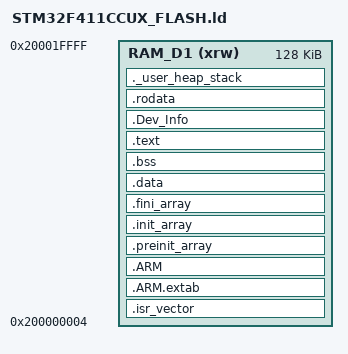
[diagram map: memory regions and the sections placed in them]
/*
******************************************************************************
**
** @file        : LinkerScript.ld
**
** @author      : Auto-generated by STM32CubeIDE
**
** @brief       : Linker script for STM32F411CCUx Device from STM32F4 series
**                      256Kbytes FLASH
**                      128Kbytes RAM
**
**                Set heap size, stack size and stack location according
**                to application requirements.
**
**                Set memory bank area and size if external memory is used
**
**  Target      : STMicroelectronics STM32
**
**  Distribution: The file is distributed as is, without any warranty
**                of any kind.
**
******************************************************************************
** @attention
**
** Copyright (c) 2023 STMicroelectronics.
** All rights reserved.
**
** This software is licensed under terms that can be found in the LICENSE file
** in the root directory of this software component.
** If no LICENSE file comes with this software, it is provided AS-IS.
**
******************************************************************************
*/

/* Entry Point */
ENTRY(Init)

/* Generate 2 segment for loader code and device info */
PHDRS {Loader PT_LOAD ; SgInfo PT_LOAD ; }

/* Highest address of the user mode stack */
_estack = ORIGIN(RAM_D1) + LENGTH(RAM_D1); /* end of "RAM" Ram type memory */

_Min_Heap_Size = 0x200; /* required amount of heap */
_Min_Stack_Size = 0x400; /* required amount of stack */

/* Memories definition */
MEMORY
{
  RAM_D1    (xrw)    : ORIGIN = 0x200000004,   LENGTH = 128K-4
}

/* Sections */
SECTIONS
{
  /* The startup code into "FLASH" Rom type memory */
  .isr_vector :
  {
  	. = . + 0x1FC; /* ISR vector offset */
    . = ALIGN(4);
    KEEP(*(.isr_vector)) /* Startup code */
    . = ALIGN(4);
  } >RAM_D1 :Loader

  .ARM.extab   : {
    . = ALIGN(4);
    *(.ARM.extab* .gnu.linkonce.armextab.*)
    . = ALIGN(4);
  } >RAM_D1 :Loader

  .ARM : {
    __exidx_start = .;
    *(.ARM.exidx*)
    __exidx_end = .;
  } >RAM_D1 :Loader

  .preinit_array     :
  {
    PROVIDE_HIDDEN (__preinit_array_start = .);
    KEEP (*(.preinit_array*))
    PROVIDE_HIDDEN (__preinit_array_end = .);
  } >RAM_D1 :Loader

  .init_array :
  {
    PROVIDE_HIDDEN (__init_array_start = .);
    KEEP (*(SORT(.init_array.*)))
    KEEP (*(.init_array*))
    PROVIDE_HIDDEN (__init_array_end = .);
  } >RAM_D1 :Loader

  .fini_array :
  {
    PROVIDE_HIDDEN (__fini_array_start = .);
    KEEP (*(SORT(.fini_array.*)))
    KEEP (*(.fini_array*))
    PROVIDE_HIDDEN (__fini_array_end = .);
  } >RAM_D1 :Loader

  /* Used by the startup to initialize data */
  _sidata = LOADADDR(.data);

  /* Initialized data sections into "RAM" Ram type memory */
  .data :
  {
    . = ALIGN(4);
    _sdata = .;        /* create a global symbol at data start */
    *(.data)           /* .data sections */
    *(.data*)          /* .data* sections */

    . = ALIGN(4);
    _edata = .;        /* define a global symbol at data end */

  } >RAM_D1 :Loader

  /* Uninitialized data section into "RAM" Ram type memory */
  . = ALIGN(4);
  .bss :
  {
    /* This is used by the startup in order to initialize the .bss section */
    _sbss = .;         /* define a global symbol at bss start */
    __bss_start__ = _sbss;
    *(.bss)
    *(.bss*)
    *(COMMON)

    . = ALIGN(4);
    _ebss = .;         /* define a global symbol at bss end */
    __bss_end__ = _ebss;
  } >RAM_D1 :Loader

  /* The program code and other data into "FLASH" Rom type memory */
  .text :
  {
    . = ALIGN(4);
    *(.text)           /* .text sections (code) */
    *(.text*)          /* .text* sections (code) */
    *(.glue_7)         /* glue arm to thumb code */
    *(.glue_7t)        /* glue thumb to arm code */
    *(.eh_frame)

    KEEP (*(.init))
    KEEP (*(.fini))
	KEEP (*Loader_Src.o ( .text* ))
    . = ALIGN(4);
    _etext = .;        /* define a global symbols at end of code */
  } >RAM_D1 :Loader
  
  .Dev_Info :
  {
	  __Dev_info_START = .;
	    *(.Dev_info*)
	    KEEP(*(.Dev_info))
	    __Dev_info_END = .;
   } >RAM_D1 :SgInfo
	 
 /* Constant data into "FLASH" Rom type memory */
  .rodata :
  {
    . = ALIGN(4);
    *(.rodata)         /* .rodata sections (constants, strings, etc.) */
    *(.rodata*)        /* .rodata* sections (constants, strings, etc.) */
    . = ALIGN(4);
  } >RAM_D1 :Loader
	 
  /* User_heap_stack section, used to check that there is enough "RAM" Ram  type memory left */
  ._user_heap_stack :
  {
    . = ALIGN(8);
    PROVIDE ( end = . );
    PROVIDE ( _end = . );
    . = . + _Min_Heap_Size;
    . = . + _Min_Stack_Size;
    . = ALIGN(8);
  } >RAM_D1 :Loader
 
  /* Remove information from the compiler libraries */
  /DISCARD/ :
  {
    libc.a ( * )
    libm.a ( * )
    libgcc.a ( * )
  }

  .ARM.attributes 0 : { *(.ARM.attributes) }
}
